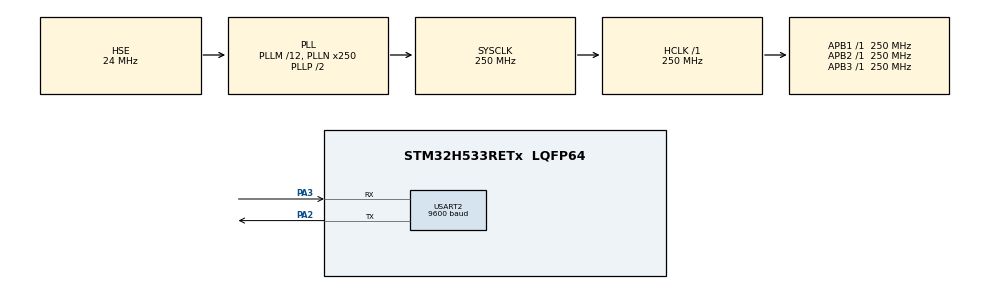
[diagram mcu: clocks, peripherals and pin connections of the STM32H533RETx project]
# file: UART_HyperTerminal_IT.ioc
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CORTEX_M33_NS.userName=CORTEX_M33
Mcu.Family=STM32H5
Mcu.Name=STM32H533RETx
Mcu.Package=LQFP64
NVIC.PriorityGroup=NVIC_PRIORITYGROUP_4
NVIC.USART2_IRQn=true\:0\:0\:false\:false\:true\:true\:true\:true
PA2.Mode=Asynchronous
PA2.Signal=USART2_TX
PA3.Mode=Asynchronous
PA3.Signal=USART2_RX
PH0-OSC_IN(PH0).Mode=HSE-External-Oscillator
PH0-OSC_IN(PH0).Signal=RCC_OSC_IN
PH1-OSC_OUT(PH1).Mode=HSE-External-Oscillator
PH1-OSC_OUT(PH1).Signal=RCC_OSC_OUT
ProjectManager.HeapSize=0x200
ProjectManager.StackSize=0x400
ProjectManager.TargetToolchain=EWARM V9.20
RCC.ADCFreq_Value=250000000
RCC.AHBFreq_Value=250000000
RCC.APB1Freq_Value=250000000
RCC.APB1TimFreq_Value=250000000
RCC.APB2Freq_Value=250000000
RCC.APB2TimFreq_Value=250000000
RCC.APB3Freq_Value=250000000
RCC.CSI_VALUE=4000000
RCC.CortexFreq_Value=250000000
RCC.EPOD_VALUE=24000000
RCC.HCLKFreq_Value=250000000
RCC.HSE_VALUE=24000000
RCC.HSI48_VALUE=48000000
RCC.HSI_VALUE=64000000
RCC.LSE_VALUE=32768
RCC.LSIRC_VALUE=32000
RCC.PLLM=12
RCC.PLLN=250
RCC.PLLSourceVirtual=RCC_PLL1_SOURCE_HSE
RCC.SYSCLKFreq_VALUE=250000000
RCC.SYSCLKSource=RCC_SYSCLKSOURCE_PLLCLK
RCC.USBFreq_Value=48000000
RCC.VCOOutputFreq_Value=500000000
USART2.AutoBaudRateEnableParam=UART_ADVFEATURE_AUTOBAUDRATE_DISABLE
USART2.BaudRate=9600
USART2.Parity=PARITY_ODD
USART2.VirtualMode=VM_ASYNC
USART2.WordLength=WORDLENGTH_8B
VP_ICACHE_VS_ICACHE.Mode=DefaultMode
VP_PWR_VS_DBSignals.Mode=DisableDeadBatterySignals
VP_PWR_VS_LPOM.Mode=PowerOptimisation
VP_PWR_VS_SECSignals.Mode=Security/Privilege
board=custom

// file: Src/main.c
/* USER CODE BEGIN Header */
/**
  ******************************************************************************
  * @file           : main.c
  * @brief            This sample code shows how to use UART HAL API to transmit
  *                   and receive a data buffer with a communication process based on
  *                   Interrupt transfer.
  *                   The communication is done with the Hyperterminal PC application.
  ******************************************************************************
  * @attention
  *
  * Copyright (c) 2023 STMicroelectronics.
  * All rights reserved.
  *
  * This software is licensed under terms that can be found in the LICENSE file
  * in the root directory of this software component.
  * If no LICENSE file comes with this software, it is provided AS-IS.
  *
  ******************************************************************************
  */
/* USER CODE END Header */
#include "main.h"

UART_HandleTypeDef huart2;

/* USER CODE BEGIN PV */
/* Buffer used for transmission */
uint8_t aTxStartMessage[] = "\n\r ****UART-Hyperterminal communication based on IT ****\n\r Enter 10 characters using keyboard :\n\r";
uint8_t aTxEndMessage[] = "\n\r Example Finished\n\r";

/* Buffer used for reception */
uint8_t aRxBuffer[RXBUFFERSIZE];
/* USER CODE END PV */

void SystemClock_Config(void);
static void MX_GPIO_Init(void);
static void MX_USART2_UART_Init(void);
static void MX_ICACHE_Init(void);

int main(void)
{

  /* MCU Configuration--------------------------------------------------------*/

  /* Reset of all peripherals, Initializes the Flash interface and the Systick. */
  HAL_Init();

  /* Configure the system clock */
  SystemClock_Config();

  /* USER CODE BEGIN SysInit */
  /* Configure LED2 */
  BSP_LED_Init(LED2);
  /* USER CODE END SysInit */

  /* Initialize all configured peripherals */
  MX_GPIO_Init();
  MX_USART2_UART_Init();
  MX_ICACHE_Init();
  /* USER CODE BEGIN 2 */

  /*##-1- Start the transmission process #####################################*/
  /* While the UART in reception process, user can transmit data through
     "aTxStartMessage" buffer */
  if(HAL_UART_Transmit_IT(&huart2, (uint8_t*)aTxStartMessage, TXSTARTMESSAGESIZE)!= HAL_OK)
  {
    /* Transfer error in transmission process */
    Error_Handler();
  }

  /*##-2- Put UART peripheral in reception process ###########################*/
  /* Any data received will be stored in "aRxBuffer" buffer : the number max of
     data received is 10 */
  if(HAL_UART_Receive_IT(&huart2, (uint8_t *)aRxBuffer, RXBUFFERSIZE) != HAL_OK)
  {
    /* Transfer error in reception process */
    Error_Handler();
  }

  /*##-3- Wait for the end of the transfer ###################################*/
  /*  Before starting a new communication transfer, you need to check the current
      state of the peripheral; if it is busy you need to wait for the end of current
      transfer before starting a new one.
      For simplicity reasons, this example is just waiting till the end of the
      transfer, but application may perform other tasks while transfer operation
      is ongoing. */
  while (HAL_UART_GetState(&huart2) != HAL_UART_STATE_READY)
  {
  }

  /*##-4- Send the received Buffer ###########################################*/
  if(HAL_UART_Transmit_IT(&huart2, (uint8_t*)aRxBuffer, RXBUFFERSIZE)!= HAL_OK)
  {
    /* Transfer error in transmission process */
    Error_Handler();
  }

  /*##-5- Wait for the end of the transfer ###################################*/
  /*  Before starting a new communication transfer, you need to check the current
      state of the peripheral; if it is busy you need to wait for the end of current
      transfer before starting a new one.
      For simplicity reasons, this example is just waiting till the end of the
      transfer, but application may perform other tasks while transfer operation
      is ongoing. */
  while (HAL_UART_GetState(&huart2) != HAL_UART_STATE_READY)
  {
  }

  /*##-6- Send the End Message ###############################################*/
  if(HAL_UART_Transmit_IT(&huart2, (uint8_t*)aTxEndMessage, TXENDMESSAGESIZE)!= HAL_OK)
  {
    /* Transfer error in transmission process */
    Error_Handler();
  }

  /*##-7- Wait for the end of the transfer ###################################*/
  while (HAL_UART_GetState(&huart2) != HAL_UART_STATE_READY)
  {
  }

  /* Turn on LED2 if test passes then enter infinite loop */
  BSP_LED_On(LED2);

  /* USER CODE END 2 */

  /* Infinite loop */
  while (1)
  {

  }
}

void SystemClock_Config(void)
{
  RCC_OscInitTypeDef RCC_OscInitStruct = {0};
  RCC_ClkInitTypeDef RCC_ClkInitStruct = {0};

  /** Configure the main internal regulator output voltage
  */
  __HAL_PWR_VOLTAGESCALING_CONFIG(PWR_REGULATOR_VOLTAGE_SCALE0);

  while(!__HAL_PWR_GET_FLAG(PWR_FLAG_VOSRDY)) {}

  /** Initializes the RCC Oscillators according to the specified parameters
  * in the RCC_OscInitTypeDef structure.
  */
  RCC_OscInitStruct.OscillatorType = RCC_OSCILLATORTYPE_HSE;
  RCC_OscInitStruct.HSEState = RCC_HSE_ON;
  RCC_OscInitStruct.PLL.PLLState = RCC_PLL_ON;
  RCC_OscInitStruct.PLL.PLLSource = RCC_PLL1_SOURCE_HSE;
  RCC_OscInitStruct.PLL.PLLM = 12;
  RCC_OscInitStruct.PLL.PLLN = 250;
  RCC_OscInitStruct.PLL.PLLP = 2;
  RCC_OscInitStruct.PLL.PLLQ = 2;
  RCC_OscInitStruct.PLL.PLLR = 2;
  RCC_OscInitStruct.PLL.PLLRGE = RCC_PLL1_VCIRANGE_1;
  RCC_OscInitStruct.PLL.PLLVCOSEL = RCC_PLL1_VCORANGE_WIDE;
  RCC_OscInitStruct.PLL.PLLFRACN = 0;
  if (HAL_RCC_OscConfig(&RCC_OscInitStruct) != HAL_OK)
  {
    Error_Handler();
  }

  /** Initializes the CPU, AHB and APB buses clocks
  */
  RCC_ClkInitStruct.ClockType = RCC_CLOCKTYPE_HCLK|RCC_CLOCKTYPE_SYSCLK
                              |RCC_CLOCKTYPE_PCLK1|RCC_CLOCKTYPE_PCLK2
                              |RCC_CLOCKTYPE_PCLK3;
  RCC_ClkInitStruct.SYSCLKSource = RCC_SYSCLKSOURCE_PLLCLK;
  RCC_ClkInitStruct.AHBCLKDivider = RCC_SYSCLK_DIV1;
  RCC_ClkInitStruct.APB1CLKDivider = RCC_HCLK_DIV1;
  RCC_ClkInitStruct.APB2CLKDivider = RCC_HCLK_DIV1;
  RCC_ClkInitStruct.APB3CLKDivider = RCC_HCLK_DIV1;

  if (HAL_RCC_ClockConfig(&RCC_ClkInitStruct, FLASH_LATENCY_5) != HAL_OK)
  {
    Error_Handler();
  }

  /** Configure the programming delay
  */
  __HAL_FLASH_SET_PROGRAM_DELAY(FLASH_PROGRAMMING_DELAY_2);
}

static void MX_ICACHE_Init(void)
{

  /** Enable instruction cache (default 2-ways set associative cache)
  */
  if (HAL_ICACHE_Enable() != HAL_OK)
  {
    Error_Handler();
  }

}

static void MX_USART2_UART_Init(void)
{

  huart2.Instance = USART2;
  huart2.Init.BaudRate = 9600;
  huart2.Init.WordLength = UART_WORDLENGTH_8B;
  huart2.Init.StopBits = UART_STOPBITS_1;
  huart2.Init.Parity = UART_PARITY_ODD;
  huart2.Init.Mode = UART_MODE_TX_RX;
  huart2.Init.HwFlowCtl = UART_HWCONTROL_NONE;
  huart2.Init.OverSampling = UART_OVERSAMPLING_16;
  huart2.Init.OneBitSampling = UART_ONE_BIT_SAMPLE_DISABLE;
  huart2.Init.ClockPrescaler = UART_PRESCALER_DIV1;
  huart2.AdvancedInit.AdvFeatureInit = UART_ADVFEATURE_NO_INIT;
  if (HAL_UART_Init(&huart2) != HAL_OK)
  {
    Error_Handler();
  }
  if (HAL_UARTEx_SetTxFifoThreshold(&huart2, UART_TXFIFO_THRESHOLD_1_8) != HAL_OK)
  {
    Error_Handler();
  }
  if (HAL_UARTEx_SetRxFifoThreshold(&huart2, UART_RXFIFO_THRESHOLD_1_8) != HAL_OK)
  {
    Error_Handler();
  }
  if (HAL_UARTEx_DisableFifoMode(&huart2) != HAL_OK)
  {
    Error_Handler();
  }

}

static void MX_GPIO_Init(void)
{

  /* GPIO Ports Clock Enable */
  __HAL_RCC_GPIOH_CLK_ENABLE();
  __HAL_RCC_GPIOA_CLK_ENABLE();

}

/* USER CODE BEGIN 4 */

/**
  * @brief  Tx Transfer completed callback
  * @param  UartHandle: UART handle.
  * @note   This example shows a simple way to report end of IT Tx transfer, and
  *         you can add your own implementation.
  * @retval None
  */
void HAL_UART_TxCpltCallback(UART_HandleTypeDef *UartHandle)
{
}

/**
  * @brief  Rx Transfer completed callback
  * @param  UartHandle: UART handle
  * @note   This example shows a simple way to report end of IT Rx transfer, and
  *         you can add your own implementation.
  * @retval None
  */
void HAL_UART_RxCpltCallback(UART_HandleTypeDef *UartHandle)
{
}

/**
  * @brief  UART error callbacks
  * @param  UartHandle: UART handle
  * @note   This example shows a simple way to report transfer error, and you can
  *         add your own implementation.
  * @retval None
  */
void HAL_UART_ErrorCallback(UART_HandleTypeDef *UartHandle)
{
  /* Turn LED2 off: Transfer error in reception/transmission process */
  BSP_LED_Off(LED2);
}

/* USER CODE END 4 */

void Error_Handler(void)
{
  /* USER CODE BEGIN Error_Handler_Debug */
  /* User can add his own implementation to report the HAL error return state */
  __disable_irq();
  while (1)
  {
    /* Toggle LED2 for error */
    BSP_LED_Toggle(LED2);
    HAL_Delay(500);
  }
  /* USER CODE END Error_Handler_Debug */
}
